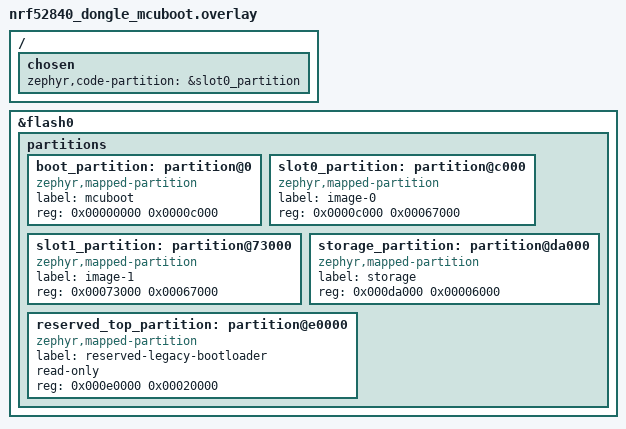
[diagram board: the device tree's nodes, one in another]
/ {
	chosen {
		zephyr,code-partition = &slot0_partition;
	};
};

&flash0 {
	/delete-node/ partitions;

	partitions {
		ranges;
		#address-cells = <1>;
		#size-cells = <1>;

		boot_partition: partition@0 {
			compatible = "zephyr,mapped-partition";
			label = "mcuboot";
			reg = <0x00000000 0x0000c000>;
		};

		slot0_partition: partition@c000 {
			compatible = "zephyr,mapped-partition";
			label = "image-0";
			reg = <0x0000c000 0x00067000>;
		};

		slot1_partition: partition@73000 {
			compatible = "zephyr,mapped-partition";
			label = "image-1";
			reg = <0x00073000 0x00067000>;
		};

		storage_partition: partition@da000 {
			compatible = "zephyr,mapped-partition";
			label = "storage";
			reg = <0x000da000 0x00006000>;
		};

		reserved_top_partition: partition@e0000 {
			compatible = "zephyr,mapped-partition";
			label = "reserved-legacy-bootloader";
			read-only;
			reg = <0x000e0000 0x00020000>;
		};
	};
};
